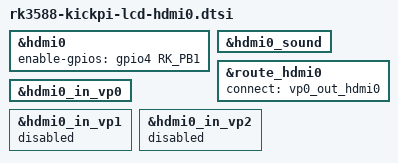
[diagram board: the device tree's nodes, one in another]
&hdmi0 {
	enable-gpios = <&gpio4 RK_PB1 GPIO_ACTIVE_HIGH>;
	status = "okay";
};

&hdmi0_sound {
	status = "okay";
};

&route_hdmi0 {
    connect = <&vp0_out_hdmi0>;
	status = "okay";
};

&hdmi0_in_vp0 {
	status = "okay";
};

&hdmi0_in_vp1 {
	status = "disabled";
};

&hdmi0_in_vp2 {
	status = "disabled";
};
